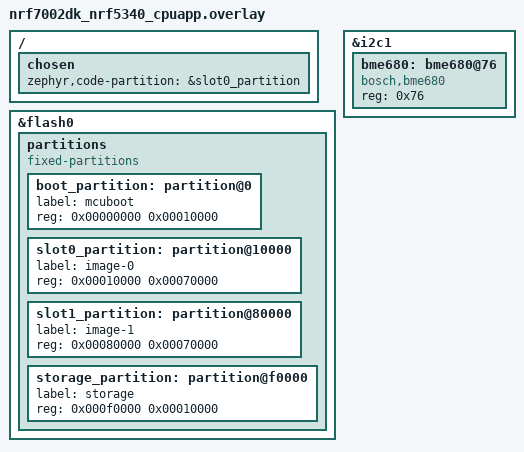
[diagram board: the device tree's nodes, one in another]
/*
 * Example devicetree overlay — adjust for your board and flash layout.
 * Verify partition sizes against Nordic nRF5340 + external flash if used.
 */

/ {
	chosen {
		zephyr,code-partition = &slot0_partition;
	};

};

&flash0 {
	partitions {
		compatible = "fixed-partitions";
		#address-cells = <1>;
		#size-cells = <1>;

		boot_partition: partition@0 {
			label = "mcuboot";
			reg = <0x00000000 0x00010000>;
		};

		slot0_partition: partition@10000 {
			label = "image-0";
			reg = <0x00010000 0x00070000>;
		};

		slot1_partition: partition@80000 {
			label = "image-1";
			reg = <0x00080000 0x00070000>;
		};

		storage_partition: partition@f0000 {
			label = "storage";
			reg = <0x000f0000 0x00010000>;
		};
	};
};

/* Example I2C sensor — enable driver in prj.conf */
&i2c1 {
	status = "okay";
	bme680: bme680@76 {
		compatible = "bosch,bme680";
		reg = <0x76>;
	};
};
